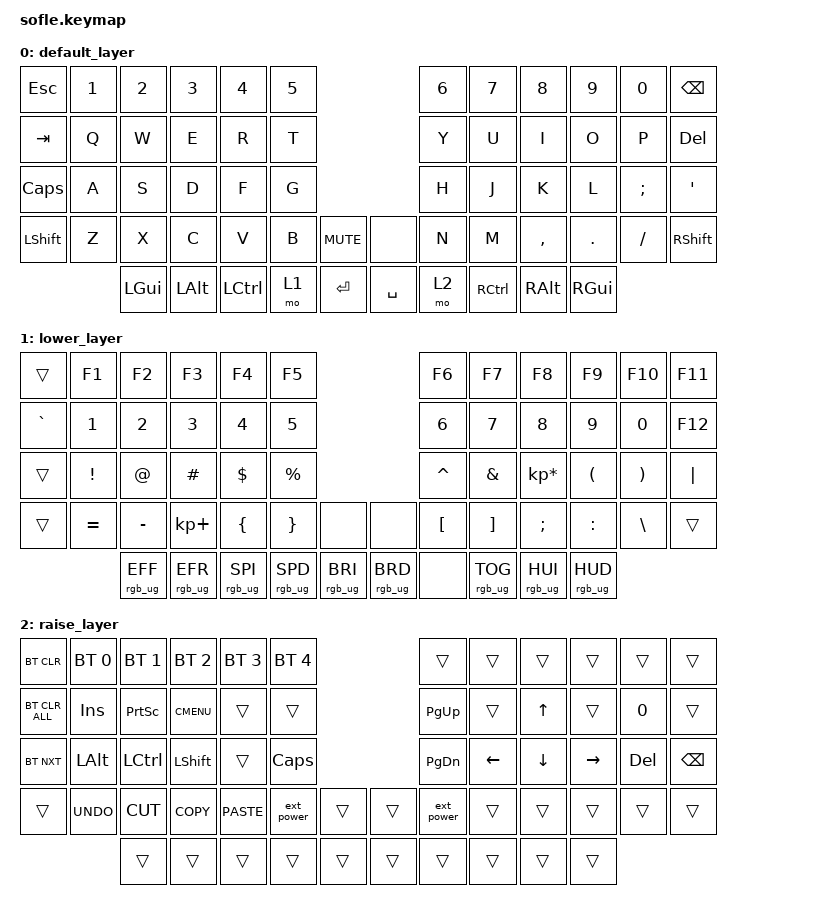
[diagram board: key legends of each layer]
/* spell-checker: disable */
/*
 * Copyright (c) 2020 The ZMK Contributors
 *
 * SPDX-License-Identifier: MIT
 */


#include <behaviors.dtsi>
#include <dt-bindings/zmk/bt.h>
#include <dt-bindings/zmk/ext_power.h>
#include <dt-bindings/zmk/keys.h>
#include <dt-bindings/zmk/outputs.h>
#include <dt-bindings/zmk/rgb.h>

&led_strip {
    chain-length = <35>;
};

&left_encoder {
    resolution = <2>;
};


/ {
    keymap {
        compatible = "zmk,keymap";

        default_layer {
// ------------------------------------------------------------------------------------------------------------
// |  ESC  |  1  |  2  |  3   |  4   |  5   |                   |  6   |  7    |  8    |  9   |   0   | BKSPC|Revi
// | SHIFT |  Z  |  X  |  C   |  V   |  B   |  MUTE  |  |       |  N   |  M    |  ,    |  .   |   /   | SHIFT |
//               | GUI | ALT  | CTRL | LOWER|  ENTER |  | SPACE | RAISE| CTRL  | ALT   | GUI  |
            bindings = <
&kp ESC   &kp N1 &kp N2   &kp N3   &kp N4    &kp N5                      &kp N6 &kp N7    &kp N8    &kp N9   &kp N0   &kp BSPC
&kp TAB   &kp Q  &kp W    &kp E    &kp R     &kp T                       &kp Y  &kp U     &kp I     &kp O    &kp P    &kp DEL
&kp CLCK  &kp A  &kp S    &kp D    &kp F     &kp G                       &kp H  &kp J     &kp K     &kp L    &kp SEMI &kp SQT
&kp LSHFT &kp Z  &kp X    &kp C    &kp V     &kp B  &kp C_MUTE &none     &kp N  &kp M     &kp COMMA &kp DOT  &kp FSLH &kp RSHFT
                 &kp LGUI &kp LALT &kp LCTRL &mo 1  &kp RET    &kp SPACE &mo 2  &kp RCTRL &kp RALT  &kp RGUI
            >;

            sensor-bindings = <&inc_dec_kp C_VOL_DN C_VOL_UP &inc_dec_kp PG_DN PG_UP>;
        };

        lower_layer {
// TODO: Some binds are waiting for shifted keycode support.
// ------------------------------------------------------------------------------------------------------------
// |       |  F1 |   F2  |   F3  |   F4  |   F5  |                  |   F6  |   F7   |  F8   |  F9  |  F10  |  F11  |
// | `     |   1 |    2  |   3   |   4   |   5   |                  |   6   |    7   |   8   |   9  |    0  |  F12  |
// |       |  !  |   @   |   #   |   $   |   %   |                  |   ^   |   &    |  *    |  (   |   )   |   |   |
// |       |  =  |   -   |   +   |   {   |   }   |       |  |       |   [   |   ]    |  ;    |  :   |   \   |       |
//               |RGB_EFF|RGB_EFR|RGB_SPI|RGB_SPD|RGB_BRI|  |RGB_BRD|       | RGB_TOG|RGB_HUI|RGB_HUD|
            bindings = <
&trans    &kp F1    &kp F2              &kp F3          &kp F4          &kp F5                                          &kp F6      &kp F7          &kp F8          &kp F9          &kp F10         &kp F11
&kp GRAVE &kp N1    &kp N2              &kp N3          &kp N4          &kp N5                                          &kp N6      &kp N7          &kp N8          &kp N9          &kp N0          &kp F12
&trans    &kp EXCL  &kp AT              &kp HASH        &kp DLLR        &kp PRCNT                                       &kp CARET   &kp AMPS        &kp KP_MULTIPLY &kp LPAR        &kp RPAR        &kp PIPE
&trans    &kp EQUAL &kp MINUS           &kp KP_PLUS     &kp LBRC        &kp RBRC        &none           &none           &kp LBKT    &kp RBKT        &kp SEMI        &kp COLON       &kp BSLH        &trans
                    &rgb_ug RGB_EFF     &rgb_ug RGB_EFR &rgb_ug RGB_SPI &rgb_ug RGB_SPD &rgb_ug RGB_BRI &rgb_ug RGB_BRD &none       &rgb_ug RGB_TOG &rgb_ug RGB_HUI &rgb_ug RGB_HUD
            >;

            sensor-bindings = <&inc_dec_kp C_VOL_DN C_VOL_UP &inc_dec_kp PG_DN PG_UP>;
        };

        raise_layer {
// ------------------------------------------------------------------------------------------------------------
// |BTCLR   | BT1  | BT2  |  BT3  |  BT4  |  BT5 |                |      |      |       |      |       |       |       |
// |BTCLRALL| INS  | PSCR | GUI   |       |      |                | PGUP |      |   ^   |      |       |       |
// |BTNXT   | ALT  | CTRL | SHIFT |       | CAPS |                | PGDN |   <- |   v   |  ->  |  DEL  | BKSPC |
// |        | UNDO | CUT  | COPY  | PASTE |EP_OFF|      |  |      |EP_OFF|      |       |      |       |       |
//              |      |       |       |      |      |  |      |      |      |       |      |
            bindings = <
&bt BT_CLR      &bt BT_SEL 0 &bt BT_SEL 1 &bt BT_SEL 2 &bt BT_SEL 3 &bt BT_SEL 4             &trans &trans    &trans   &trans    &trans  &trans
&bt BT_CLR_ALL  &kp INS      &kp PSCRN    &kp K_CMENU  &trans       &trans                   &kp PG_UP  &trans    &kp UP   &trans    &kp N0  &trans
&bt BT_NXT      &kp LALT     &kp LCTRL    &kp LSHFT    &trans       &kp CLCK                 &kp PG_DN  &kp LEFT  &kp DOWN &kp RIGHT &kp DEL &kp BSPC
&trans          &kp K_UNDO   &kp K_CUT    &kp K_COPY   &kp K_PASTE  &ext_power  &trans   &trans  &ext_power &trans    &trans   &trans    &trans  &trans
                        &trans       &trans       &trans       &trans  &trans   &trans  &trans    &trans    &trans   &trans
            >;

            sensor-bindings = <&inc_dec_kp C_VOL_DN C_VOL_UP &inc_dec_kp PG_DN PG_UP>;
        };
    };
};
